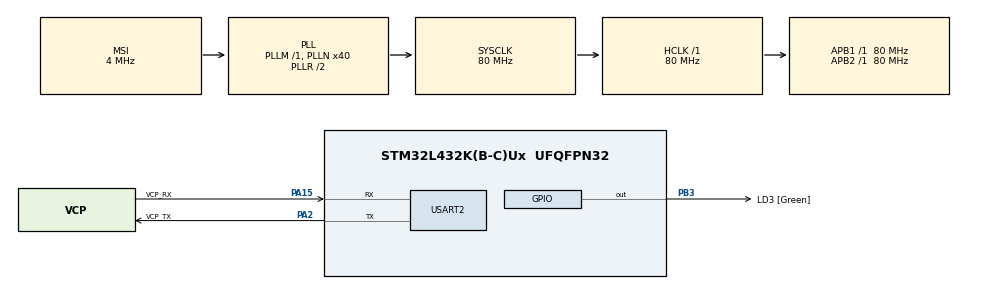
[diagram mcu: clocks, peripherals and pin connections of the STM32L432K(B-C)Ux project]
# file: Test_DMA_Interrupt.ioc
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Dma.Request0=USART2_RX
Dma.Request1=USART2_TX
Dma.USART2_RX.0.Direction=DMA_PERIPH_TO_MEMORY
Dma.USART2_RX.0.Instance=DMA1_Channel6
Dma.USART2_RX.0.MemDataAlignment=DMA_MDATAALIGN_BYTE
Dma.USART2_RX.0.MemInc=DMA_MINC_ENABLE
Dma.USART2_RX.0.Mode=DMA_NORMAL
Dma.USART2_RX.0.PeriphDataAlignment=DMA_PDATAALIGN_BYTE
Dma.USART2_RX.0.PeriphInc=DMA_PINC_DISABLE
Dma.USART2_RX.0.Priority=DMA_PRIORITY_VERY_HIGH
Dma.USART2_TX.1.Direction=DMA_MEMORY_TO_PERIPH
Dma.USART2_TX.1.Instance=DMA1_Channel7
Dma.USART2_TX.1.MemDataAlignment=DMA_MDATAALIGN_BYTE
Dma.USART2_TX.1.MemInc=DMA_MINC_ENABLE
Dma.USART2_TX.1.Mode=DMA_NORMAL
Dma.USART2_TX.1.PeriphDataAlignment=DMA_PDATAALIGN_BYTE
Dma.USART2_TX.1.PeriphInc=DMA_PINC_DISABLE
Dma.USART2_TX.1.Priority=DMA_PRIORITY_VERY_HIGH
Mcu.Family=STM32L4
Mcu.Name=STM32L432K(B-C)Ux
Mcu.Package=UFQFPN32
NVIC.DMA1_Channel6_IRQn=true\:0\:0\:false\:false\:true\:false\:true
NVIC.DMA1_Channel7_IRQn=true\:0\:0\:false\:false\:true\:false\:true
NVIC.PriorityGroup=NVIC_PRIORITYGROUP_4
NVIC.USART2_IRQn=true\:0\:0\:false\:false\:true\:true\:true
PA0.GPIO_Label=MCO [High speed clock in]
PA0.Mode=HSE-External-Clock-Source-for-LittleOrca
PA0.Signal=RCC_CK_IN
PA13\ (JTMS-SWDIO).GPIO_Label=SWDIO
PA13\ (JTMS-SWDIO).Mode=Serial_Wire
PA13\ (JTMS-SWDIO).Signal=SYS_JTMS-SWDIO
PA14\ (JTCK-SWCLK).GPIO_Label=SWCLK
PA14\ (JTCK-SWCLK).Mode=Serial_Wire
PA14\ (JTCK-SWCLK).Signal=SYS_JTCK-SWCLK
PA15\ (JTDI).GPIO_Label=VCP_RX
PA15\ (JTDI).Mode=Asynchronous
PA15\ (JTDI).Signal=USART2_RX
PA2.GPIO_Label=VCP_TX
PA2.Mode=Asynchronous
PA2.Signal=USART2_TX
PB3\ (JTDO-TRACESWO).GPIO_Label=LD3 [Green]
PB3\ (JTDO-TRACESWO).Signal=GPIO_Output
PC14-OSC32_IN\ (PC14).Mode=LSE-External-Oscillator
PC14-OSC32_IN\ (PC14).Signal=RCC_OSC32_IN
PC15-OSC32_OUT\ (PC15).Mode=LSE-External-Oscillator
PC15-OSC32_OUT\ (PC15).Signal=RCC_OSC32_OUT
ProjectManager.HeapSize=0x200
ProjectManager.StackSize=0x400
ProjectManager.TargetToolchain=STM32CubeIDE
RCC.AHBFreq_Value=80000000
RCC.APB1Freq_Value=80000000
RCC.APB1TimFreq_Value=80000000
RCC.APB2Freq_Value=80000000
RCC.APB2TimFreq_Value=80000000
RCC.CortexFreq_Value=80000000
RCC.HCLKFreq_Value=80000000
RCC.HSE_VALUE=8000000
RCC.HSI16_VALUE=16000000
RCC.HSI48_VALUE=48000000
RCC.HSI_VALUE=16000000
RCC.MSI_VALUE=4000000
RCC.PLLMUL=RCC_PLLMUL_4
RCC.PLLN=40
RCC.SYSCLKFreq_VALUE=80000000
RCC.SYSCLKSource=RCC_SYSCLKSOURCE_PLLCLK
RCC.VCOOutputFreq_Value=160000000
USART2.VirtualMode-Asynchronous=VM_ASYNC
board=NUCLEO-L432KC

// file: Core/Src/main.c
/* USER CODE BEGIN Header */
/**
  ******************************************************************************
  * @file           : main.c
  * @brief          : Main program body
  ******************************************************************************
  * @attention
  *
  * <h2><center>&copy; Copyright (c) 2021 STMicroelectronics.
  * All rights reserved.</center></h2>
  *
  * This software component is licensed by ST under BSD 3-Clause license,
  * the "License"; You may not use this file except in compliance with the
  * License. You may obtain a copy of the License at:
  *                        opensource.org/licenses/BSD-3-Clause
  *
  ******************************************************************************
  */
/* USER CODE END Header */
#include "main.h"
#include "dma.h"
#include "usart.h"
#include "gpio.h"

/* USER CODE BEGIN Includes */
#include "string.h"
/* USER CODE END Includes */

/* USER CODE BEGIN PV */

typedef enum _BUFFER_StateTypedef
{
  BUFFER_OFFSET_NONE = 0,
  BUFFER_OFFSET_HALF,
  BUFFER_OFFSET_FULL,
}BUFFER_StateTypeDef;

BUFFER_StateTypeDef buff_Status = BUFFER_OFFSET_NONE;

/* Mensaje a enviar y longitud del mensaje */
uint8_t mensaje[] = "0123456789abcdefghij";
uint8_t mensaje_length = 20;

/* Buffer para envío de DMA */
uint8_t buffTx[10];
int counter = 0;
/* USER CODE END PV */

void SystemClock_Config(void);

int main(void)
{

  /* MCU Configuration--------------------------------------------------------*/

  /* Reset of all peripherals, Initializes the Flash interface and the Systick. */
  HAL_Init();

  /* Configure the system clock */
  SystemClock_Config();

  /* Initialize all configured peripherals */
  MX_GPIO_Init();
  MX_DMA_Init();
  MX_USART2_UART_Init();
  /* USER CODE BEGIN 2 */

  memcpy(buffTx, "0123456789", 10);
  HAL_UART_Transmit_DMA(&huart2, buffTx, mensaje_length/2);

  /* USER CODE END 2 */

  /* Infinite loop */
  /* USER CODE BEGIN WHILE */
  while (1)
  {
	  switch(buff_Status)
	  {
		  case BUFFER_OFFSET_HALF:
			  {
				  memcpy(buffTx, "abcde", 5);
				  buff_Status = BUFFER_OFFSET_NONE;
			  }
	  	  	  break;

		  case BUFFER_OFFSET_FULL:
			  {
				  memcpy(&buffTx[5], "fghij", 5);
				  buff_Status = BUFFER_OFFSET_NONE;
				  counter++;
			  }
	  	  	  break;

		  case BUFFER_OFFSET_NONE:
		  default:
			  break;
	  }

	  if(counter > 10)
	  {
		  HAL_UART_DMAStop(&huart2); /* Se para el envío una vez completado */
	  }
    /* USER CODE END WHILE */

  }
}

void SystemClock_Config(void)
{
  RCC_OscInitTypeDef RCC_OscInitStruct = {0};
  RCC_ClkInitTypeDef RCC_ClkInitStruct = {0};
  RCC_PeriphCLKInitTypeDef PeriphClkInit = {0};

  /** Configure LSE Drive Capability
  */
  HAL_PWR_EnableBkUpAccess();
  __HAL_RCC_LSEDRIVE_CONFIG(RCC_LSEDRIVE_LOW);
  /** Initializes the RCC Oscillators according to the specified parameters
  * in the RCC_OscInitTypeDef structure.
  */
  RCC_OscInitStruct.OscillatorType = RCC_OSCILLATORTYPE_LSE|RCC_OSCILLATORTYPE_MSI;
  RCC_OscInitStruct.LSEState = RCC_LSE_OFF;
  RCC_OscInitStruct.MSIState = RCC_MSI_ON;
  RCC_OscInitStruct.MSICalibrationValue = 0;
  RCC_OscInitStruct.MSIClockRange = RCC_MSIRANGE_6;
  RCC_OscInitStruct.PLL.PLLState = RCC_PLL_ON;
  RCC_OscInitStruct.PLL.PLLSource = RCC_PLLSOURCE_MSI;
  RCC_OscInitStruct.PLL.PLLM = 1;
  RCC_OscInitStruct.PLL.PLLN = 40;
  RCC_OscInitStruct.PLL.PLLP = RCC_PLLP_DIV7;
  RCC_OscInitStruct.PLL.PLLQ = RCC_PLLQ_DIV2;
  RCC_OscInitStruct.PLL.PLLR = RCC_PLLR_DIV2;
  if (HAL_RCC_OscConfig(&RCC_OscInitStruct) != HAL_OK)
  {
    Error_Handler();
  }
  /** Initializes the CPU, AHB and APB buses clocks
  */
  RCC_ClkInitStruct.ClockType = RCC_CLOCKTYPE_HCLK|RCC_CLOCKTYPE_SYSCLK
                              |RCC_CLOCKTYPE_PCLK1|RCC_CLOCKTYPE_PCLK2;
  RCC_ClkInitStruct.SYSCLKSource = RCC_SYSCLKSOURCE_PLLCLK;
  RCC_ClkInitStruct.AHBCLKDivider = RCC_SYSCLK_DIV1;
  RCC_ClkInitStruct.APB1CLKDivider = RCC_HCLK_DIV1;
  RCC_ClkInitStruct.APB2CLKDivider = RCC_HCLK_DIV1;

  if (HAL_RCC_ClockConfig(&RCC_ClkInitStruct, FLASH_LATENCY_4) != HAL_OK)
  {
    Error_Handler();
  }
  PeriphClkInit.PeriphClockSelection = RCC_PERIPHCLK_USART2;
  PeriphClkInit.Usart2ClockSelection = RCC_USART2CLKSOURCE_PCLK1;
  if (HAL_RCCEx_PeriphCLKConfig(&PeriphClkInit) != HAL_OK)
  {
    Error_Handler();
  }
  /** Configure the main internal regulator output voltage
  */
  if (HAL_PWREx_ControlVoltageScaling(PWR_REGULATOR_VOLTAGE_SCALE1) != HAL_OK)
  {
    Error_Handler();
  }
  /** Enable MSI Auto calibration
  */
  HAL_RCCEx_EnableMSIPLLMode();
}

/* USER CODE BEGIN 4 */

/* Half transfer completed */
void HAL_UART_TxHalfCpltCallback(UART_HandleTypeDef *huart)
{
	if(huart->Instance == USART2)
	{
		buff_Status = BUFFER_OFFSET_HALF;
	}
}

/* Full transfer completed */
void HAL_UART_TxCpltCallback(UART_HandleTypeDef *huart)
{
	if(huart->Instance == USART2)
	{
		buff_Status = BUFFER_OFFSET_FULL;
	}
}

/* USER CODE END 4 */

void Error_Handler(void)
{
  __disable_irq();
  while (1)
  {
  }
}

/************************ (C) COPYRIGHT STMicroelectronics *****END OF FILE****/
